# BE-U1000 register map
Vendor: BAIKAL ELECTRONICS, JSC; File version: 1.0
CPU: RISC-V r0p0, little endian, no MPU, no FPU, 3 interrupt priority bits
Registers are 32-bit, read-write, reset 0x0 unless marked. A register's access mark holds for its fields unless they carry their own. Offsets are from the block's base; [hi:lo] are bit positions; {n}, {i} and the like mark numbered series.

## ADC0 — Analog to Digital Converter
Base 0x14001000
Same registers: ADC1 0x14002000, ADC2 0x14003000
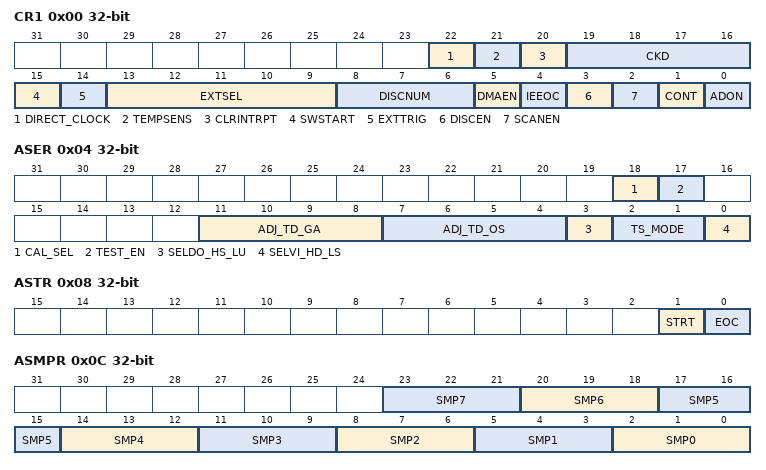
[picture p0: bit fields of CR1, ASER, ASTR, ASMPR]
0x00 CR1 — Control register 1
  [22] DIRECT_CLOCK — ADC clock from CLKI
    0=DISABLE; 1=ENABLE
  [21] TEMPSENS — Temperature sensor
    0=DISABLE; 1=ENABLE
  [20] CLRINTRPT — Clear interrupt
    0=DISABLE; 1=ENABLE
  [19:16] CKD — Clock division
    0=DIV1 (CK_INT is not divided); {v}=DIV{v+1} (CK_INT is divided by {v+1}) (v=1..15)
  [15] SWSTART — Start of conversion
    0=DISABLE; 1=ENABLE
  [14] EXTTRIG — External trigger conversion mode enable
    0=DISABLE; 1=ENABLE
  [13:9] EXTSEL — External event select
    {v}=External event {v} (v=0..19)
  [8:6] DISCNUM — Discontinuous mode channel count
    0=1RANK; {v}={v+1}RANKS (v=1..7)
  [5] DMAEN — DMA enable
    0=DISABLE (DMA transfer is disabled); 1=ENABLE (DMA transfer is enabled)
  [4] IEEOC — EOC interrupt enable
    0=DISABLE; 1=ENABLE
  [3] DISCEN — Discontinuous mode enable
    0=DISABLE (Discontinuous mode is disabled); 1=ENABLE (Discontinuous mode is enabled)
  [2] SCANEN — Scan mode enable
    0=DISABLE (Scan mode is disabled); 1=ENABLE (Scan mode is enabled)
  [1] CONT — Continuous conversion enable
    0=DISABLE (Continuous conversion is disabled); 1=ENABLE (Continuous conversion is enabled)
  [0] ADON — ADC on/off
    0=DISABLE; 1=ENABLE
0x04 ASER — Set register
  [18] CAL_SEL — Calibration mode enable
    0=DISABLE; 1=ENABLE
  [17] TEST_EN — Test mode enable
    0=DISABLE; 1=ENABLE
  [11:8] ADJ_TD_GA — Temperature sensor gain adjustment signal
  [7:4] ADJ_TD_OS — Temperature sensor offset adjustment signal
  [3] SELDO_HS_LU — Output data type selection
    0=UNSIGNED (Unsigned data); 1=SIGNED (Signed data)
  [2:1] TS_MODE — Filter mode of the temperature sensor
    0=BYPASS (Bypass internal lowpass filter); 1=AVG64 (64 times average); 2=AVG128 (128 times average); 3=AVG256 (256 times average)
  [0] SELVI_HD_LS — Input type selection
    0=SINGLE (Single end); 1=DIFF (Differential)
0x08 ASTR — Status register
  [1] STRT — Start of conversion
    0=DISABLE; 1=ENABLE
  [0] EOC — End of conversion
    0=DISABLE; 1=ENABLE
0x0C ASMPR — Sample time register
  [all] fields
    0=0CYCLES; 1=25CYCLES; 2=50CYCLES; 3=75CYCLES; 4=125CYCLES; 5=175CYCLES; 6=225CYCLES; 7=275CYCLES
  [3n+2:3n] SMP{n} (n=0..7) — Sample count {n}
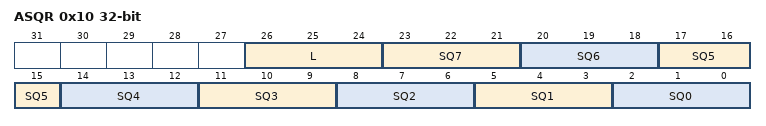
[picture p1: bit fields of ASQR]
0x10 ASQR — Sequence register
  [26:24] L — The length of the sequence
    0=1RANK; {v}={v+1}RANKS (v=1..7)
  [3n+2:3n] SQ{n} (n=0..7) — Channel {n}
0x14 ADR — Data register
  [11:0] ADR — ADC data

## AHB — Advanced High-performance Bus
Base 0x15108000
0x00 PL — Arbitration Priority Master n Register
  [3:0] PL — Arbitration priority for master
0x3C EBTCOUNT — Early Burst Termination Count Register
  [9:0] EBTCOUNT — Early burst termination count
0x40 EBT_EN — Early Burst Termination Enable Register
  [0] EBT_EN — Early burst termination enable
    0=DISABLE; 1=ENABLE
0x44 EBT — Early Burst Termination Register
  [0] EBT — Early burst termination
    0=DISABLE; 1=ENABLE
0x48 DFLT_MASTER — Default Master ID Number Register
  [3:0] DFLT_MASTER — Default master ID number
0x90 VERSION_ID — Component Version ID Register

## AXI — Advanced eXtensible Interface
Base 0x1400B000
0x400 VERSION_ID — Component Version ID Register
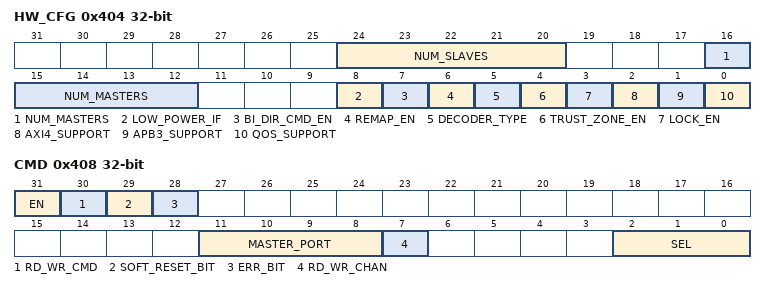
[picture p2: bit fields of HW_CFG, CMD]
0x404 HW_CFG — Hardware Configuration Register
  [24:20] NUM_SLAVES — Number of AXI slaves
  [16:12] NUM_MASTERS — Number of AXI masters
  [8] LOW_POWER_IF — Include/exclude low-power interface
    0=DISABLE; 1=ENABLE
  [7] BI_DIR_CMD_EN — Support for Enable Bi-directional Command
    0=DISABLE; 1=ENABLE
  [6] REMAP_EN — Support for Enable Remap mode
    0=DISABLE; 1=ENABLE
  [5] DECODER_TYPE — Use of External/Internal Decoder
    0=DISABLE; 1=ENABLE
  [4] TRUST_ZONE_EN — Support for Enable Trust Zone
    0=DISABLE; 1=ENABLE
  [3] LOCK_EN — Support for Enable Lock transactions
    0=DISABLE; 1=ENABLE
  [2] AXI4_SUPPORT — AXI4 features support
    0=DISABLE; 1=ENABLE
  [1] APB3_SUPPORT
    0=DISABLE; 1=ENABLE
  [0] QOS_SUPPORT
    0=DISABLE; 1=ENABLE
0x408 CMD — Command Enable Register
  [31] EN — Command enable
    0=DISABLE; 1=ENABLE
  [30] RD_WR_CMD — Read command / write command
    0=READ (Read command); 1=WRITE (Write command)
  [29] SOFT_RESET_BIT — Internal register reset
    0=DISABLE; 1=ENABLE
  [28] ERR_BIT — Error bit
    0=DISABLE; 1=ENABLE
  [11:8] MASTER_PORT — Master port ID
    {v}=Master port {v+1} (v=0..15)
  [7] RD_WR_CHAN — Read address channel / write address channel
    0=WRITE (The command is for write address channel); 1=READ (The command is for read address channel)
  [2:0] SEL — Command selection for internal registers
    0=BURST_REG_EN (BURSTINESS_REGULATOR_EN register address offset); 1=PEAK_RATE_XCT_RATE (PEAK_RATE_XCT_RATE register address offset); 2=QOS_VALUE (QOS_VALUE register address offset); 3=SLV_READY (SLV_READY register address offset)
0x40C DATA
  [31:0] DATA — Data to be written into / read from the QoS internal register
